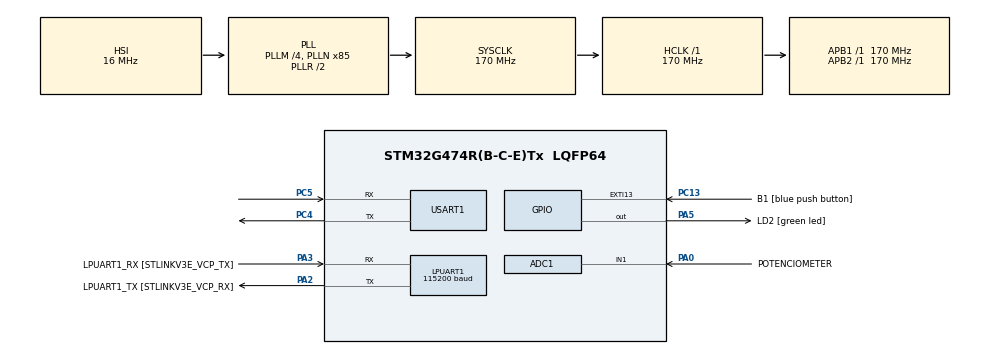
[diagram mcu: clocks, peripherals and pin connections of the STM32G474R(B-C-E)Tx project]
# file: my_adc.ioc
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Mcu.Family=STM32G4
RCC.CortexFreq_Value=170000000
ADC1.ContinuousConvMode=ENABLE
Dma.ADC1.0.Polarity=HAL_DMAMUX_REQ_GEN_RISING
PA14.GPIO_Label=T_SWCLK
PA0.GPIO_Label=POTENCIOMETER
LPUART1.WordLength=UART_WORDLENGTH_8B
PC5.Mode=Asynchronous
PC13.GPIO_Label=B1 [blue push button]
RCC.SYSCLKSource=RCC_SYSCLKSOURCE_PLLCLK
ProjectManager.StackSize=0x400
RCC.HCLKFreq_Value=170000000
RCC.APB2TimFreq_Value=170000000
Dma.ADC1.0.Direction=DMA_PERIPH_TO_MEMORY
Dma.ADC1.0.MemDataAlignment=DMA_MDATAALIGN_HALFWORD
RCC.AHBFreq_Value=170000000
NVIC.EXTI15_10_IRQn=true\:0\:0\:false\:false\:true\:true\:true
ADC1.Channel-0\#ChannelRegularConversion=ADC_CHANNEL_1
RCC.HSE_VALUE=24000000
RCC.ADC12Freq_Value=170000000
RCC.RTCClockSelection=RCC_RTCCLKSOURCE_LSE
PC14-OSC32_IN.Mode=LSE-External-Oscillator
PA14.Mode=Serial_Wire
Dma.ADC1.0.PeriphInc=DMA_PINC_DISABLE
PA0.Mode=IN1-Single-Ended
VP_SYS_VS_DBSignals.Mode=DisableDeadBatterySignals
ADC1.SamplingTime-0\#ChannelRegularConversion=ADC_SAMPLETIME_640CYCLES_5
PA0.Signal=ADC1_IN1
Mcu.Package=LQFP64
PA2.GPIO_Label=LPUART1_TX [STLINKV3E_VCP_RX]
RCC.APB1TimFreq_Value=170000000
PC5.Signal=USART1_RX
PF1-OSC_OUT.Mode=HSE-External-Oscillator
Dma.Request0=ADC1
PF1-OSC_OUT.Signal=RCC_OSC_OUT
Dma.ADC1.0.EventEnable=DISABLE
PC4.Mode=Asynchronous
RCC.HSI48_VALUE=48000000
PA3.Signal=LPUART1_RX
PB3.GPIO_Label=T_SWO
PC15-OSC32_OUT.Mode=LSE-External-Oscillator
Dma.ADC1.0.Instance=DMA1_Channel2
ADC1.Rank-0\#ChannelRegularConversion=1
Dma.ADC1.0.SyncRequestNumber=1
ADC1.OffsetNumber-0\#ChannelRegularConversion=ADC_OFFSET_NONE
PC13.Signal=GPXTI13
PC4.Signal=USART1_TX
RCC.EXTERNAL_CLOCK_VALUE=12288000
PC14-OSC32_IN.Signal=RCC_OSC32_IN
USART1.VirtualMode-Asynchronous=VM_ASYNC
PA13.Signal=SYS_JTMS-SWDIO
PA3.Mode=Asynchronous
Dma.ADC1.0.PeriphDataAlignment=DMA_PDATAALIGN_HALFWORD
NVIC.DMA1_Channel2_IRQn=true\:0\:0\:false\:false\:true\:false\:true
ProjectManager.TargetToolchain=SW4STM32
Dma.ADC1.0.Mode=DMA_CIRCULAR
Dma.ADC1.0.SignalID=NONE
Dma.ADC1.0.SyncSignalID=NONE
Dma.ADC1.0.Priority=DMA_PRIORITY_LOW
RCC.USBFreq_Value=170000000
PC15-OSC32_OUT.Signal=RCC_OSC32_OUT
PF0-OSC_IN.Mode=HSE-External-Oscillator
PA5.Signal=GPIO_Output
board=NUCLEO-G474RE
RCC.VCOOutputFreq_Value=340000000
Dma.ADC1.0.SyncPolarity=HAL_DMAMUX_SYNC_NO_EVENT
RCC.ADC345Freq_Value=170000000
RCC.APB2Freq_Value=170000000
ADC1.DMAContinuousRequests=ENABLE
ADC1.NbrOfConversion=1
PA13.Mode=Serial_Wire
Mcu.Name=STM32G474R(B-C-E)Tx
LPUART1.BaudRate=115200
PA13.GPIO_Label=T_SWDIO
PA2.Signal=LPUART1_TX
PB3.Signal=SYS_JTDO-SWO
RCC.SYSCLKFreq_VALUE=170000000
ADC1.master=1
PA5.GPIO_Label=LD2 [green led]
Dma.ADC1.0.RequestNumber=1
Dma.ADC1.0.SyncEnable=DISABLE
PA14.Signal=SYS_JTCK-SWCLK
Dma.ADC1.0.MemInc=DMA_MINC_ENABLE
ProjectManager.HeapSize=0x200
RCC.HSI_VALUE=16000000
NVIC.PriorityGroup=NVIC_PRIORITYGROUP_4
ADC1.NbrOfConversionFlag=1
RCC.PLLM=RCC_PLLM_DIV4
RCC.PLLN=85
PA2.Mode=Asynchronous
PF0-OSC_IN.Signal=RCC_OSC_IN
RCC.APB1Freq_Value=170000000
ADC1.ClockPrescaler=ADC_CLOCK_ASYNC_DIV256
PA3.GPIO_Label=LPUART1_RX [STLINKV3E_VCP_TX]

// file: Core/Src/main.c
/* USER CODE BEGIN Header */
/**
  ******************************************************************************
  * @file           : main.c
  * @brief          : Main program body
  ******************************************************************************
  * @attention
  *
  * <h2><center>&copy; Copyright (c) 2021 STMicroelectronics.
  * All rights reserved.</center></h2>
  *
  * This software component is licensed by ST under BSD 3-Clause license,
  * the "License"; You may not use this file except in compliance with the
  * License. You may obtain a copy of the License at:
  *                        opensource.org/licenses/BSD-3-Clause
  *
  ******************************************************************************
  */
/* USER CODE END Header */
#include "main.h"
/* USER CODE BEGIN Includes */
#include <stdio.h>
#include <string.h>
/* USER CODE END Includes */

/* USER CODE BEGIN PD */
#define ADC_BUFFER_SIZE 4096
/* USER CODE END PD */

ADC_HandleTypeDef hadc1;
DMA_HandleTypeDef hdma_adc1;

UART_HandleTypeDef hlpuart1;
UART_HandleTypeDef huart1;
DMA_HandleTypeDef hdma_usart1_tx;

/* USER CODE BEGIN PV */
uint16_t adcBuffer[ADC_BUFFER_SIZE];
uint16_t adcDataCount = 0;
char message[10];
/* USER CODE END PV */

void SystemClock_Config(void);
static void MX_GPIO_Init(void);
static void MX_DMA_Init(void);
static void MX_LPUART1_UART_Init(void);
static void MX_ADC1_Init(void);
static void MX_USART1_UART_Init(void);

int main(void)
{

  /* MCU Configuration--------------------------------------------------------*/

  /* Reset of all peripherals, Initializes the Flash interface and the Systick. */
  HAL_Init();

  /* Configure the system clock */
  SystemClock_Config();

  /* Initialize all configured peripherals */
  MX_GPIO_Init();
  MX_DMA_Init();
  MX_LPUART1_UART_Init();
  MX_ADC1_Init();
  MX_USART1_UART_Init();
  /* USER CODE BEGIN 2 */
  HAL_ADC_Start_DMA(&hadc1, (uint32_t *) adcBuffer, ADC_BUFFER_SIZE);
  /* USER CODE END 2 */

  /* Infinite loop */
  while (1)
  {

  }
}

void SystemClock_Config(void)
{
  RCC_OscInitTypeDef RCC_OscInitStruct = {0};
  RCC_ClkInitTypeDef RCC_ClkInitStruct = {0};
  RCC_PeriphCLKInitTypeDef PeriphClkInit = {0};

  /** Configure the main internal regulator output voltage
  */
  HAL_PWREx_ControlVoltageScaling(PWR_REGULATOR_VOLTAGE_SCALE1_BOOST);
  /** Initializes the RCC Oscillators according to the specified parameters
  * in the RCC_OscInitTypeDef structure.
  */
  RCC_OscInitStruct.OscillatorType = RCC_OSCILLATORTYPE_HSI;
  RCC_OscInitStruct.HSIState = RCC_HSI_ON;
  RCC_OscInitStruct.HSICalibrationValue = RCC_HSICALIBRATION_DEFAULT;
  RCC_OscInitStruct.PLL.PLLState = RCC_PLL_ON;
  RCC_OscInitStruct.PLL.PLLSource = RCC_PLLSOURCE_HSI;
  RCC_OscInitStruct.PLL.PLLM = RCC_PLLM_DIV4;
  RCC_OscInitStruct.PLL.PLLN = 85;
  RCC_OscInitStruct.PLL.PLLP = RCC_PLLP_DIV2;
  RCC_OscInitStruct.PLL.PLLQ = RCC_PLLQ_DIV2;
  RCC_OscInitStruct.PLL.PLLR = RCC_PLLR_DIV2;
  if (HAL_RCC_OscConfig(&RCC_OscInitStruct) != HAL_OK)
  {
    Error_Handler();
  }
  /** Initializes the CPU, AHB and APB buses clocks
  */
  RCC_ClkInitStruct.ClockType = RCC_CLOCKTYPE_HCLK|RCC_CLOCKTYPE_SYSCLK
                              |RCC_CLOCKTYPE_PCLK1|RCC_CLOCKTYPE_PCLK2;
  RCC_ClkInitStruct.SYSCLKSource = RCC_SYSCLKSOURCE_PLLCLK;
  RCC_ClkInitStruct.AHBCLKDivider = RCC_SYSCLK_DIV1;
  RCC_ClkInitStruct.APB1CLKDivider = RCC_HCLK_DIV1;
  RCC_ClkInitStruct.APB2CLKDivider = RCC_HCLK_DIV1;

  if (HAL_RCC_ClockConfig(&RCC_ClkInitStruct, FLASH_LATENCY_4) != HAL_OK)
  {
    Error_Handler();
  }
  /** Initializes the peripherals clocks
  */
  PeriphClkInit.PeriphClockSelection = RCC_PERIPHCLK_USART1|RCC_PERIPHCLK_LPUART1
                              |RCC_PERIPHCLK_ADC12;
  PeriphClkInit.Usart1ClockSelection = RCC_USART1CLKSOURCE_PCLK2;
  PeriphClkInit.Lpuart1ClockSelection = RCC_LPUART1CLKSOURCE_PCLK1;
  PeriphClkInit.Adc12ClockSelection = RCC_ADC12CLKSOURCE_SYSCLK;
  if (HAL_RCCEx_PeriphCLKConfig(&PeriphClkInit) != HAL_OK)
  {
    Error_Handler();
  }
}

static void MX_ADC1_Init(void)
{

  ADC_MultiModeTypeDef multimode = {0};
  ADC_ChannelConfTypeDef sConfig = {0};

  /** Common config
  */
  hadc1.Instance = ADC1;
  hadc1.Init.ClockPrescaler = ADC_CLOCK_SYNC_PCLK_DIV4;
  hadc1.Init.Resolution = ADC_RESOLUTION_12B;
  hadc1.Init.DataAlign = ADC_DATAALIGN_RIGHT;
  hadc1.Init.GainCompensation = 0;
  hadc1.Init.ScanConvMode = ADC_SCAN_DISABLE;
  hadc1.Init.EOCSelection = ADC_EOC_SINGLE_CONV;
  hadc1.Init.LowPowerAutoWait = DISABLE;
  hadc1.Init.ContinuousConvMode = ENABLE;
  hadc1.Init.NbrOfConversion = 1;
  hadc1.Init.DiscontinuousConvMode = DISABLE;
  hadc1.Init.ExternalTrigConv = ADC_SOFTWARE_START;
  hadc1.Init.ExternalTrigConvEdge = ADC_EXTERNALTRIGCONVEDGE_NONE;
  hadc1.Init.DMAContinuousRequests = ENABLE;
  hadc1.Init.Overrun = ADC_OVR_DATA_PRESERVED;
  hadc1.Init.OversamplingMode = DISABLE;
  if (HAL_ADC_Init(&hadc1) != HAL_OK)
  {
    Error_Handler();
  }
  /** Configure the ADC multi-mode
  */
  multimode.Mode = ADC_MODE_INDEPENDENT;
  if (HAL_ADCEx_MultiModeConfigChannel(&hadc1, &multimode) != HAL_OK)
  {
    Error_Handler();
  }
  /** Configure Regular Channel
  */
  sConfig.Channel = ADC_CHANNEL_1;
  sConfig.Rank = ADC_REGULAR_RANK_1;
  sConfig.SamplingTime = ADC_SAMPLETIME_2CYCLES_5;
  sConfig.SingleDiff = ADC_SINGLE_ENDED;
  sConfig.OffsetNumber = ADC_OFFSET_NONE;
  sConfig.Offset = 0;
  if (HAL_ADC_ConfigChannel(&hadc1, &sConfig) != HAL_OK)
  {
    Error_Handler();
  }

}

static void MX_LPUART1_UART_Init(void)
{

  hlpuart1.Instance = LPUART1;
  hlpuart1.Init.BaudRate = 115200;
  hlpuart1.Init.WordLength = UART_WORDLENGTH_8B;
  hlpuart1.Init.StopBits = UART_STOPBITS_1;
  hlpuart1.Init.Parity = UART_PARITY_NONE;
  hlpuart1.Init.Mode = UART_MODE_TX_RX;
  hlpuart1.Init.HwFlowCtl = UART_HWCONTROL_NONE;
  hlpuart1.Init.OneBitSampling = UART_ONE_BIT_SAMPLE_DISABLE;
  hlpuart1.AdvancedInit.AdvFeatureInit = UART_ADVFEATURE_NO_INIT;
  if (HAL_UART_Init(&hlpuart1) != HAL_OK)
  {
    Error_Handler();
  }
  if (HAL_UARTEx_SetTxFifoThreshold(&hlpuart1, UART_TXFIFO_THRESHOLD_1_8) != HAL_OK)
  {
    Error_Handler();
  }
  if (HAL_UARTEx_SetRxFifoThreshold(&hlpuart1, UART_RXFIFO_THRESHOLD_1_8) != HAL_OK)
  {
    Error_Handler();
  }
  if (HAL_UARTEx_DisableFifoMode(&hlpuart1) != HAL_OK)
  {
    Error_Handler();
  }

}

static void MX_USART1_UART_Init(void)
{

  huart1.Instance = USART1;
  huart1.Init.BaudRate = 115200;
  huart1.Init.WordLength = UART_WORDLENGTH_8B;
  huart1.Init.StopBits = UART_STOPBITS_1;
  huart1.Init.Parity = UART_PARITY_NONE;
  huart1.Init.Mode = UART_MODE_TX_RX;
  huart1.Init.HwFlowCtl = UART_HWCONTROL_NONE;
  huart1.Init.OverSampling = UART_OVERSAMPLING_16;
  huart1.Init.OneBitSampling = UART_ONE_BIT_SAMPLE_DISABLE;
  huart1.Init.ClockPrescaler = UART_PRESCALER_DIV1;
  huart1.AdvancedInit.AdvFeatureInit = UART_ADVFEATURE_NO_INIT;
  if (HAL_UART_Init(&huart1) != HAL_OK)
  {
    Error_Handler();
  }
  if (HAL_UARTEx_SetTxFifoThreshold(&huart1, UART_TXFIFO_THRESHOLD_1_8) != HAL_OK)
  {
    Error_Handler();
  }
  if (HAL_UARTEx_SetRxFifoThreshold(&huart1, UART_RXFIFO_THRESHOLD_1_8) != HAL_OK)
  {
    Error_Handler();
  }
  if (HAL_UARTEx_DisableFifoMode(&huart1) != HAL_OK)
  {
    Error_Handler();
  }

}

static void MX_DMA_Init(void)
{

  /* DMA controller clock enable */
  __HAL_RCC_DMAMUX1_CLK_ENABLE();
  __HAL_RCC_DMA1_CLK_ENABLE();

  /* DMA interrupt init */
  /* DMA1_Channel1_IRQn interrupt configuration */
  HAL_NVIC_SetPriority(DMA1_Channel1_IRQn, 0, 0);
  HAL_NVIC_EnableIRQ(DMA1_Channel1_IRQn);
  /* DMA1_Channel2_IRQn interrupt configuration */
  HAL_NVIC_SetPriority(DMA1_Channel2_IRQn, 0, 0);
  HAL_NVIC_EnableIRQ(DMA1_Channel2_IRQn);
  /* DMAMUX_OVR_IRQn interrupt configuration */
  HAL_NVIC_SetPriority(DMAMUX_OVR_IRQn, 0, 0);
  HAL_NVIC_EnableIRQ(DMAMUX_OVR_IRQn);

}

static void MX_GPIO_Init(void)
{
  GPIO_InitTypeDef GPIO_InitStruct = {0};

  /* GPIO Ports Clock Enable */
  __HAL_RCC_GPIOC_CLK_ENABLE();
  __HAL_RCC_GPIOF_CLK_ENABLE();
  __HAL_RCC_GPIOA_CLK_ENABLE();
  __HAL_RCC_GPIOB_CLK_ENABLE();

  /*Configure GPIO pin Output Level */
  HAL_GPIO_WritePin(LD2_GPIO_Port, LD2_Pin, GPIO_PIN_RESET);

  /*Configure GPIO pin : B1_Pin */
  GPIO_InitStruct.Pin = B1_Pin;
  GPIO_InitStruct.Mode = GPIO_MODE_IT_RISING;
  GPIO_InitStruct.Pull = GPIO_NOPULL;
  HAL_GPIO_Init(B1_GPIO_Port, &GPIO_InitStruct);

  /*Configure GPIO pin : LD2_Pin */
  GPIO_InitStruct.Pin = LD2_Pin;
  GPIO_InitStruct.Mode = GPIO_MODE_OUTPUT_PP;
  GPIO_InitStruct.Pull = GPIO_NOPULL;
  GPIO_InitStruct.Speed = GPIO_SPEED_FREQ_LOW;
  HAL_GPIO_Init(LD2_GPIO_Port, &GPIO_InitStruct);

  /* EXTI interrupt init*/
  HAL_NVIC_SetPriority(EXTI15_10_IRQn, 0, 0);
  HAL_NVIC_EnableIRQ(EXTI15_10_IRQn);

}

/* USER CODE BEGIN 4 */
void HAL_ADC_ConvCpltCallback(ADC_HandleTypeDef * hadc) {

	adcDataCount = (adcDataCount == (ADC_BUFFER_SIZE - 1)) ? (adcDataCount + 1) : 0;
	sprintf(message, "%hu\r\n", adcBuffer[adcDataCount]);
	HAL_UART_Transmit(&huart1, (uint8_t *) message, strlen(message), HAL_MAX_DELAY);
}
/* USER CODE END 4 */

void Error_Handler(void)
{
}

/************************ (C) COPYRIGHT STMicroelectronics *****END OF FILE****/
